AUTOSAR XML (schema 00047)
package /Components
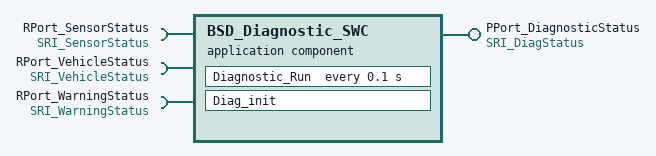
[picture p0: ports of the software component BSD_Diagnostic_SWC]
  application sw component type BSD_Diagnostic_SWC
    require port RPort_SensorStatus: required-com-specs=[{data-element=Status_Left, init-value=0}, {data-element=Status_Right, init-value=0}], required-interface=SRI_SensorStatus
    require port RPort_VehicleStatus: required-com-specs=[{data-element=Vehicle_Speed, init-value=0}, {data-element=Gear_Position, init-value=0}], required-interface=SRI_VehicleStatus
    require port RPort_WarningStatus: nonqueued-receiver-com-spec{data-element=Warning_Status, init-value=0}, required-interface=SRI_WarningStatus
    provide port PPort_DiagnosticStatus: provided-interface=SRI_DiagStatus
      provided-com-specs:
        data-element=DTC_Active_Count, init-value=0
        data-element=BSD_Available, init-value=0
        data-element=System_Health, init-value=0
    behavior untitled1_IB: handle-termination-and-restart=NO-SUPPORT
      timing event TE_Diagnostic_Run_100ms: start-on-event=Diagnostic_Run, period=0.1
      init event Event: start-on-event=Diag_init
      runnable Diagnostic_Run
        data-read-access:
          5 x access:
            IN_RPort_VehicleStatus_Gear_Position: accessed-variable=RPort_VehicleStatus.Gear_Position
            IN_RPort_SensorStatus_Status_Left: accessed-variable=RPort_SensorStatus.Status_Left
            IN_RPort_SensorStatus_Status_Right: accessed-variable=RPort_SensorStatus.Status_Right
            IN_RPort_VehicleStatus_Vehicle_Speed: accessed-variable=RPort_VehicleStatus.Vehicle_Speed
            IN_RPort_WarningStatus_Warning_Status: accessed-variable=RPort_WarningStatus.Warning_Status
        data-write-access:
          access OUT_PPort_DiagnosticStatus_DTC_Active_Count: accessed-variable=PPort_DiagnosticStatus.DTC_Active_Count
          access OUT_PPort_DiagnosticStatus_System_Health: accessed-variable=PPort_DiagnosticStatus.System_Health
          access OUT_PPort_DiagnosticStatus_BSD_Available: accessed-variable=PPort_DiagnosticStatus.BSD_Available
      runnable Diag_init
